# S1C31W74 register map
Vendor: Epson; Series: S1C31W74; File version: 1.11
CPU: CM0PLUS r0p1, little endian, MPU, no FPU, VTOR, 2 interrupt priority bits
Registers are 16-bit, read-write, reset 0x0 unless marked. A register's access mark holds for its fields unless they carry their own. Offsets are from the block's base; [hi:lo] are bit positions.

## QSPI_0 — Quad Synchronous Serial Interface channel 0
Base 0x40000690
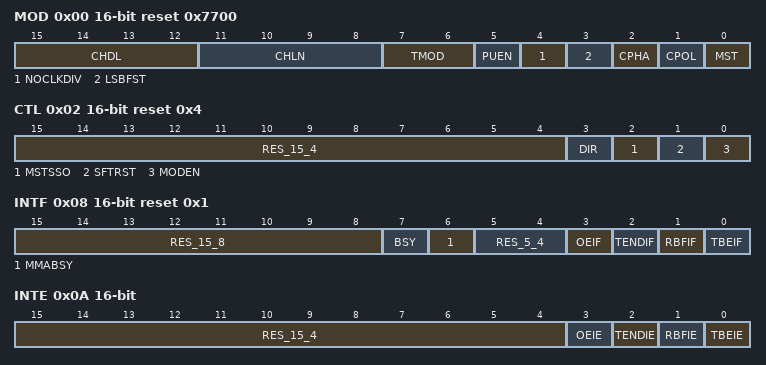
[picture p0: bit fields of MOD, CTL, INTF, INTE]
0x00 MOD reset 0x7700 — QSPI Mode Register
  [15:12] CHDL — These bits determines the number of clocks the serial output data lines will be driven
  [11:8] CHLN — These bits set the number of clocks for data transfer
  [7:6] TMOD — These bits selects the transfer mode
  [5] PUEN — Enable/Disable pull-up/down
  [4] NOCLKDIV — This bit selects QSPICLKn
  [3] LSBFST — This bit configures the data format
  [2] CPHA — This bit sets the QSPI clock phase
  [1] CPOL — This bit sets the QSPI clock polarity
  [0] MST — This bit sets the QSPI operating mode
0x02 CTL reset 0x4 — QSPI Control Register
  [15:4] RES_15_4 ro — Reserved bits
  [3] DIR — This bit set the transfer direction of SDIO
  [2] MSTSSO — This bit controls the slave select output pin in master mode only
  [1] SFTRST — This bit issues software reset to QSPI
  [0] MODEN — This bit enables the QSPI operations
0x04 TXD — Transmit Data Register
  [15:0] TXD — Transmit data
0x06 RXD ro — Receive Data Register
  [15:0] RXD — Receive data
0x08 INTF reset 0x1 — Interrupt Flag Register
  [15:8] RES_15_8 ro — Reserved bits
  [7] BSY ro — This bit indicates the QSPI operating status
  [6] MMABSY ro — This bit indicates the QSPI memory mapped access operating status
  [5:4] RES_5_4 ro — Reserved bit
  [3] OEIF ro — Overrun error interrupt
  [2] TENDIF ro — End-of-transmission interrupt
  [1] RBFIF ro — Receive buffer full interrupt
  [0] TBEIF ro — Transmit buffer empty interrupt
0x0A INTE — QSPI Interrupt Enable Register
  [15:4] RES_15_4 ro — Reserved bits
  [3] OEIE — Overrun error interrupt
    0=DISABLE; 1=ENABLE
  [2] TENDIE — End-of-transmission interrupt
    0=DISABLE; 1=ENABLE
  [1] RBFIE — Receive buffer full interrupt
    0=DISABLE; 1=ENABLE
  [0] TBEIE — Transmit buffer empty interrupt
    0=DISABLE; 1=ENABLE
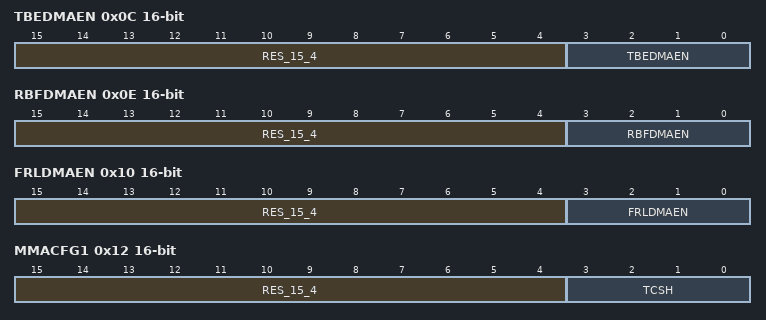
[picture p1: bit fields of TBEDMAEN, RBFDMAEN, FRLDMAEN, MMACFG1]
0x0C TBEDMAEN — TBE DMA Enable Register
  [15:4] RES_15_4 ro — Reserved bits
  [3:0] TBEDMAEN — TBE DMA request enable
0x0E RBFDMAEN — RBFDMAEN Receive Buffer Full DMA Request Enable Register
  [15:4] RES_15_4 ro — Reserved bits
  [3:0] RBFDMAEN — RBF DMA request enable
0x10 FRLDMAEN — FRLDMAEN QSPI Fifo Read Level Not Empty DMA Request Enable Register
  [15:4] RES_15_4 ro — Reserved bits
  [3:0] FRLDMAEN — FRL DMA request enable
0x12 MMACFG1 — QSPI Memory Mapped Access Configuration Register 1
  [15:4] RES_15_4 ro — Reserved bits
  [3:0] TCSH — These bits specify the number of clocks for slave select high between non-contiguous address flash memory read
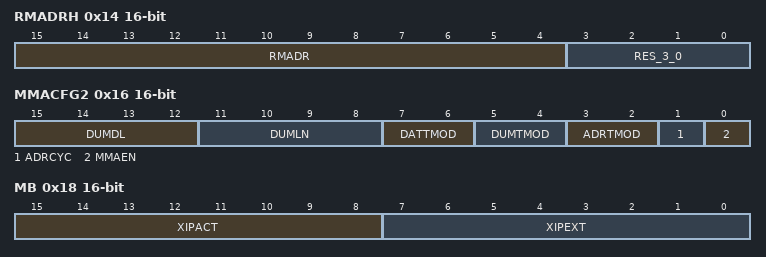
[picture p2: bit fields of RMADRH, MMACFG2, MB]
0x14 RMADRH — QSPI Remapping Start Address High Register
  [15:4] RMADR — The most significant bits of register bits will be appended to the input offset address from the system AHB-Lite bus to this QSPI module
  [3:0] RES_3_0 ro — Reserved bits
0x16 MMACFG2 — QSPI Memory Mapped Access Configuration Register 2
  [15:12] DUMDL — These bits determines the number of clocks the serial output data lines will be driven for dummy cycle
  [11:8] DUMLN — These bits set the number of clocks for dummy cycle during host memory mapped access to the external flash
  [7:6] DATTMOD — These bits specify the number of clocks for slave select high between non-contiguous address flash memory read
  [5:4] DUMTMOD — These bits selects the transfer mode for dummy cycle during host memory mapped access to the external flash
  [3:2] ADRTMOD — These bits selects the transfer mode for address cycle during host memory mapped access to the external flash
  [1] ADRCYC — This bit selects 24-bit or 32-bit address mode used during host memory mapped access to the external flash
  [0] MMAEN — This bit enables host memory mapped access to the external flash
0x18 MB — QSPI Mode Byte Register
  [15:8] XIPACT — These bit sets the mode byte for activation of XIP access during host memory mapped access to the external flash
  [7:0] XIPEXT — These bit sets the mode byte for exit of XIP access during host memory mapped access to the external flash
